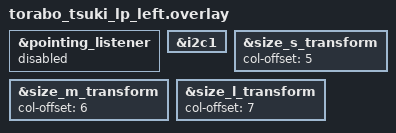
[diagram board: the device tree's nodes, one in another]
#include "torabo_tsuki_lp.dtsi"
#include <input/processors.dtsi>
#include <dt-bindings/zmk/input_transform.h>

&pointing_listener {
    status = "disabled";
};

&i2c1 {
    status = "okay";
};

&size_s_transform {
    col-offset = <5>;
};

&size_m_transform {
    col-offset = <6>;
};

&size_l_transform {
    col-offset = <7>;
};
